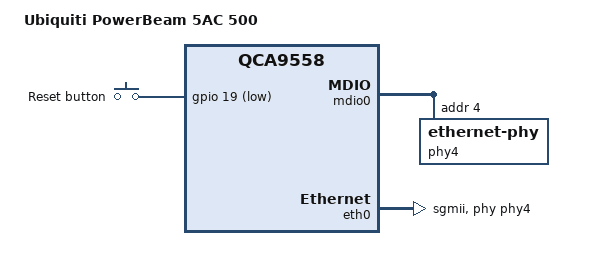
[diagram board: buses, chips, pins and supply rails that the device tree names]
// SPDX-License-Identifier: GPL-2.0-only

#include "qca955x_ubnt_xc.dtsi"

/ {
	compatible = "ubnt,powerbeam-5ac-500", "ubnt,xc", "qca,qca9558";
	model = "Ubiquiti PowerBeam 5AC 500";

	keys {
		compatible = "gpio-keys";

		reset {
			label = "Reset button";
			linux,code = <KEY_RESTART>;
			gpios = <&gpio 19 GPIO_ACTIVE_LOW>;
			debounce-interval = <60>;
		};
	};
};

&mdio0 {
	status = "okay";

	phy-mask = <4>;
	phy4: ethernet-phy@4 {
		phy-mode = "sgmii";
		reg = <4>;
		at803x-override-sgmii-link-check;
	};
};

&eth0 {
	status = "okay";

	nvmem-cells = <&macaddr_art_0>;
	nvmem-cell-names = "mac-address";
	phy-mode = "sgmii";
	phy-handle = <&phy4>;
};

&art {
	compatible = "nvmem-cells";
	#address-cells = <1>;
	#size-cells = <1>;

	macaddr_art_0: macaddr@0 {
		reg = <0x0 0x6>;
	};
};
